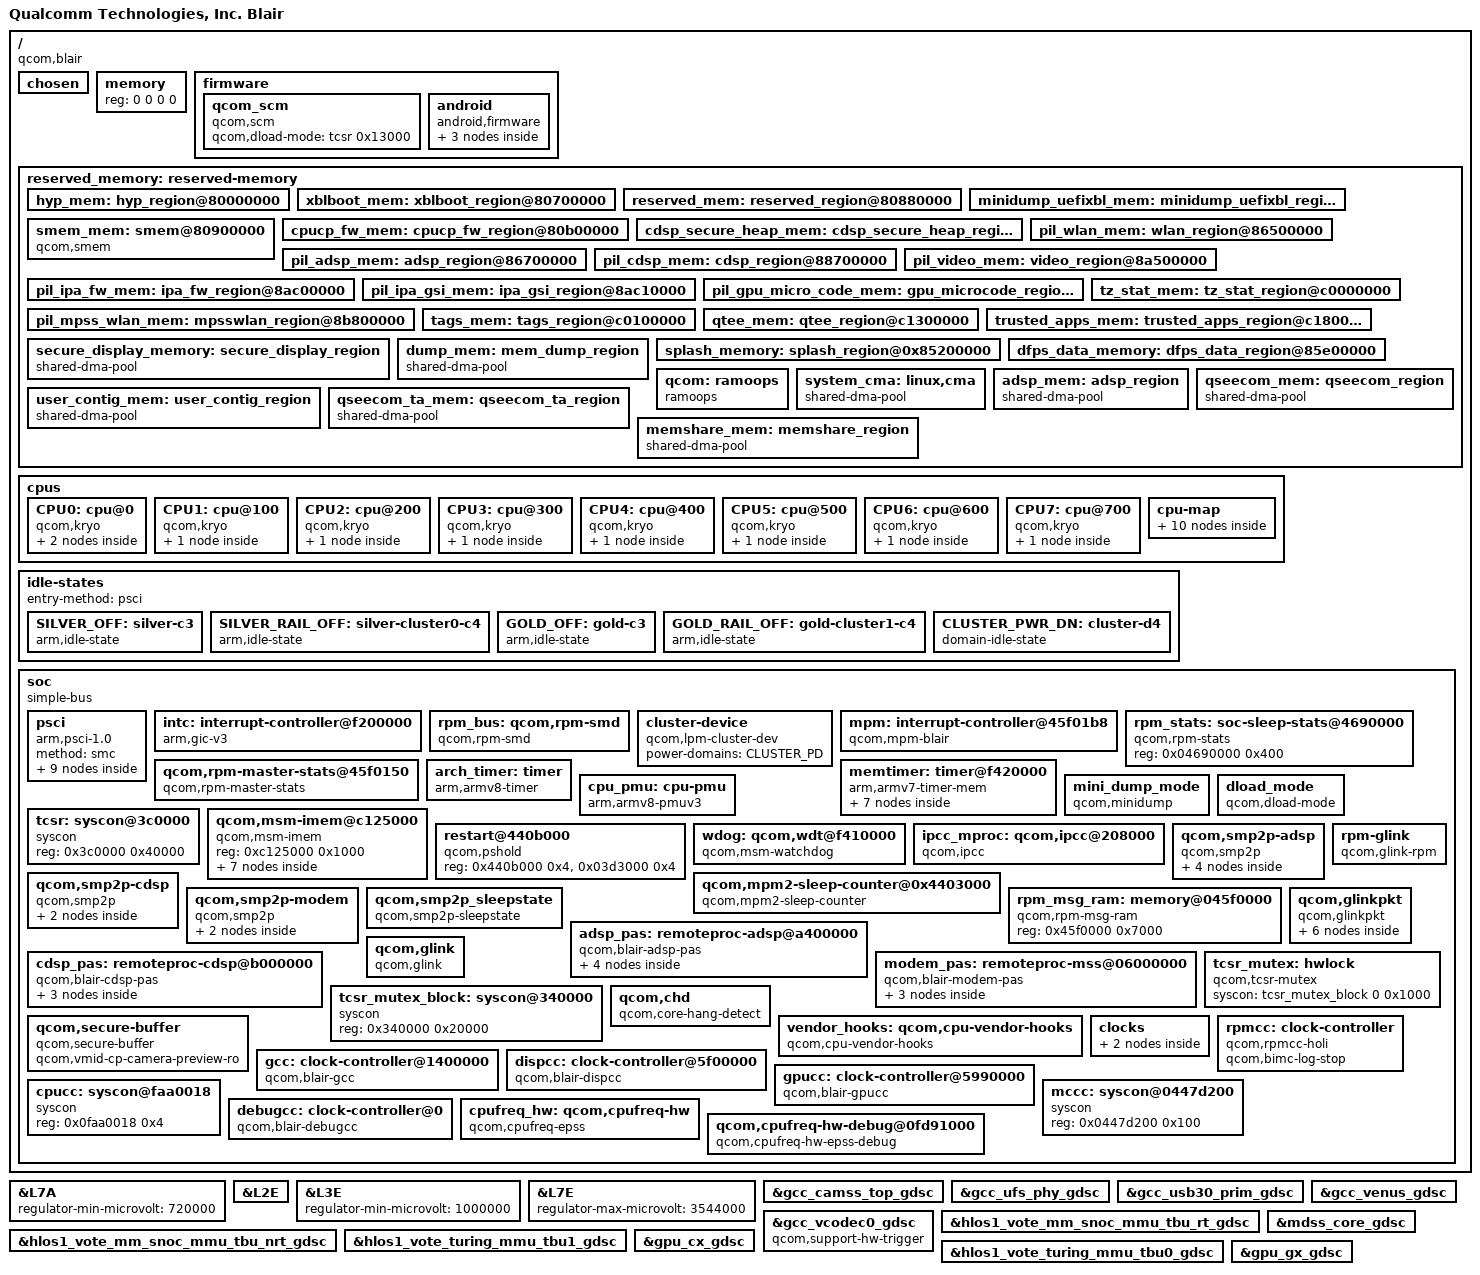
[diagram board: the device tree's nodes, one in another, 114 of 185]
#include <dt-bindings/interrupt-controller/arm-gic.h>
#include <dt-bindings/soc/qcom,ipcc.h>
#include <dt-bindings/clock/qcom,dispcc-blair.h>
#include <dt-bindings/clock/qcom,gcc-blair.h>
#include <dt-bindings/clock/qcom,gpucc-blair.h>
#include <dt-bindings/clock/qcom,rpmcc.h>

/ {
	model = "Qualcomm Technologies, Inc. Blair";
	compatible = "qcom,blair";
	qcom,msm-id = <507 0x10000>;
	interrupt-parent = <&intc>;

	#address-cells = <2>;
	#size-cells = <2>;
	chosen {
		bootargs = "log_buf_len=256K rcupdate.rcu_expedited=1 rcu_nocbs=0-7 kpti=off nmi_watchdog=0 nosoftlockup nowatchdog cpufreq.default_governor=performance";
	};

	memory { device_type = "memory"; reg = <0 0 0 0>; };

	firmware: firmware { };

	reserved_memory: reserved-memory { };

	cpus {
		#address-cells = <2>;
		#size-cells = <0>;

		CPU0: cpu@0 {
			device_type = "cpu";
			compatible = "qcom,kryo";
			reg = <0x0 0x0>;
			enable-method = "psci";
			cpu-idle-states = <&SILVER_OFF &SILVER_RAIL_OFF>;
			power-domains = <&CPU_PD0>;
			power-domain-names = "psci";
			cpu-release-addr = <0x0 0x50000000>;
			next-level-cache = <&L2_0>;
			qcom,freq-domain = <&cpufreq_hw 0>;
			L2_0: l2-cache {
			      compatible = "arm,arch-cache";
			      cache-level = <2>;
			      next-level-cache = <&L3_0>;

				L3_0: l3-cache {
				      compatible = "arm,arch-cache";
				      cache-level = <3>;
				};
			};
		};

		CPU1: cpu@100 {
			device_type = "cpu";
			compatible = "qcom,kryo";
			reg = <0x0 0x100>;
			enable-method = "psci";
			cpu-idle-states = <&SILVER_OFF &SILVER_RAIL_OFF>;
			power-domains = <&CPU_PD1>;
			power-domain-names = "psci";
			cpu-release-addr = <0x0 0x50000000>;
			next-level-cache = <&L2_1>;
			qcom,freq-domain = <&cpufreq_hw 0>;
			L2_1: l2-cache {
			      compatible = "arm,arch-cache";
			      cache-level = <2>;
			      next-level-cache = <&L3_0>;
			};
		};

		CPU2: cpu@200 {
			device_type = "cpu";
			compatible = "qcom,kryo";
			reg = <0x0 0x200>;
			enable-method = "psci";
			cpu-idle-states = <&SILVER_OFF &SILVER_RAIL_OFF>;
			power-domains = <&CPU_PD2>;
			power-domain-names = "psci";
			cpu-release-addr = <0x0 0x50000000>;
			next-level-cache = <&L2_2>;
			qcom,freq-domain = <&cpufreq_hw 0>;
			L2_2: l2-cache {
			      compatible = "arm,arch-cache";
			      cache-level = <2>;
			      next-level-cache = <&L3_0>;
			};
		};

		CPU3: cpu@300 {
			device_type = "cpu";
			compatible = "qcom,kryo";
			reg = <0x0 0x300>;
			enable-method = "psci";
			cpu-idle-states = <&SILVER_OFF &SILVER_RAIL_OFF>;
			power-domains = <&CPU_PD3>;
			power-domain-names = "psci";
			cpu-release-addr = <0x0 0x50000000>;
			next-level-cache = <&L2_3>;
			qcom,freq-domain = <&cpufreq_hw 0>;
			L2_3: l2-cache {
			      compatible = "arm,arch-cache";
			      cache-level = <2>;
			      next-level-cache = <&L3_0>;
			};
		};

		CPU4: cpu@400 {
			device_type = "cpu";
			compatible = "qcom,kryo";
			reg = <0x0 0x400>;
			enable-method = "psci";
			cpu-idle-states = <&SILVER_OFF &SILVER_RAIL_OFF>;
			power-domains = <&CPU_PD4>;
			power-domain-names = "psci";
			cpu-release-addr = <0x0 0x50000000>;
			next-level-cache = <&L2_4>;
			qcom,freq-domain = <&cpufreq_hw 0>;
			L2_4: l2-cache {
			      compatible = "arm,arch-cache";
			      cache-level = <2>;
			      next-level-cache = <&L3_0>;
			};
		};

		CPU5: cpu@500 {
			device_type = "cpu";
			compatible = "qcom,kryo";
			reg = <0x0 0x500>;
			enable-method = "psci";
			cpu-idle-states = <&SILVER_OFF &SILVER_RAIL_OFF>;
			power-domains = <&CPU_PD5>;
			power-domain-names = "psci";
			cpu-release-addr = <0x0 0x50000000>;
			next-level-cache = <&L2_5>;
			qcom,freq-domain = <&cpufreq_hw 0>;
			L2_5: l2-cache {
			      compatible = "arm,arch-cache";
			      cache-level = <2>;
			      next-level-cache = <&L3_0>;
			};
		};

		CPU6: cpu@600 {
			device_type = "cpu";
			compatible = "qcom,kryo";
			reg = <0x0 0x600>;
			enable-method = "psci";
			cpu-idle-states = <&GOLD_OFF &GOLD_RAIL_OFF>;
			power-domains = <&CPU_PD6>;
			power-domain-names = "psci";
			cpu-release-addr = <0x0 0x50000000>;
			next-level-cache = <&L2_6>;
			qcom,freq-domain = <&cpufreq_hw 1>;
			L2_6: l2-cache {
			      compatible = "arm,arch-cache";
			      cache-level = <2>;
			      next-level-cache = <&L3_0>;
			};
		};

		CPU7: cpu@700 {
			device_type = "cpu";
			compatible = "qcom,kryo";
			reg = <0x0 0x700>;
			enable-method = "psci";
			cpu-idle-states = <&GOLD_OFF &GOLD_RAIL_OFF>;
			power-domains = <&CPU_PD7>;
			power-domain-names = "psci";
			cpu-release-addr = <0x0 0x50000000>;
			next-level-cache = <&L2_7>;
			qcom,freq-domain = <&cpufreq_hw 1>;
			L2_7: l2-cache {
			      compatible = "arm,arch-cache";
			      cache-level = <2>;
			      next-level-cache = <&L3_0>;
			};
		};

		cpu-map {
			cluster0 {
				core0 {
					cpu = <&CPU0>;
				};

				core1 {
					cpu = <&CPU1>;
				};

				core2 {
					cpu = <&CPU2>;
				};

				core3 {
					cpu = <&CPU3>;
				};

				core4 {
					cpu = <&CPU4>;
				};

				core5 {
					cpu = <&CPU5>;
				};
			};

			cluster1 {
				core0 {
					cpu = <&CPU6>;
				};

				core1 {
					cpu = <&CPU7>;
				};
			};

		};
	};

	idle-states {
		entry-method = "psci";

		SILVER_OFF: silver-c3 {  /* C3 */
			compatible = "arm,idle-state";
			idle-state-name = "pc";
			entry-latency-us = <549>;
			exit-latency-us = <901>;
			min-residency-us = <1774>;
			arm,psci-suspend-param = <0x40000003>;
			local-timer-stop;
		};

		SILVER_RAIL_OFF: silver-cluster0-c4 { /* C4 */
			compatible = "arm,idle-state";
			idle-state-name = "rail-pc";
			entry-latency-us = <702>;
			exit-latency-us = <915>;
			min-residency-us = <4001>;
			arm,psci-suspend-param = <0x40000004>;
			local-timer-stop;
		};

		GOLD_OFF: gold-c3 {  /* C3 */
			compatible = "arm,idle-state";
			idle-state-name = "pc";
			entry-latency-us = <523>;
			exit-latency-us = <1244>;
			min-residency-us = <2207>;
			arm,psci-suspend-param = <0x40000003>;
			local-timer-stop;
		};

		GOLD_RAIL_OFF: gold-cluster1-c4 { /* C4 */
			compatible = "arm,idle-state";
			idle-state-name = "rail-pc";
			entry-latency-us = <526>;
			exit-latency-us = <1854>;
			min-residency-us = <5555>;
			arm,psci-suspend-param = <0x40000004>;
			local-timer-stop;
		};

		CLUSTER_PWR_DN: cluster-d4 { /* D4 */
			compatible = "domain-idle-state";
			idle-state-name = "l3-pc";
			entry-latency-us = <2752>;
			exit-latency-us = <3038>;
			min-residency-us = <6118>;
			arm,psci-suspend-param = <0x41000044>;
		};
	};

	soc: soc { };

};

#include "blair-dma-heaps.dtsi"

&reserved_memory {
	#address-cells = <2>;
	#size-cells = <2>;
	ranges;

	hyp_mem: hyp_region@80000000 {
		no-map;
		reg = <0x0 0x80000000 0x0 0x600000>;
	};

	/* only reserve part of XBL BOOT */
	xblboot_mem: xblboot_region@80700000 {
		no-map;
		reg = <0x0 0x80700000 0x0 0x100000>;
	};

	reserved_mem: reserved_region@80880000 {
		no-map;
		reg = <0x0 0x80880000 0x0 0x4000>;
	};

	minidump_uefixbl_mem: minidump_uefixbl_region@80884000 {
		no-map;
		reg = <0x0 0x80884000 0x0 0x10000>;
	};

	/* secdata can be reused by apps */

	/* smem region having compatible driver */
	smem_mem: smem@80900000 {
		compatible = "qcom,smem";
		reg = <0x0 0x80900000 0x0 0x200000>;
		hwlocks = <&tcsr_mutex 3>;
		no-map;
	};

	cpucp_fw_mem: cpucp_fw_region@80b00000 {
		no-map;
		reg = <0x0 0x80b00000 0x0 0x100000>;
	};

	cdsp_secure_heap_mem: cdsp_secure_heap_region@80c00000 {
		no-map;
		reg = <0x0 0x80c00000 0x0 0x1e00000>;
	};

	pil_wlan_mem: wlan_region@86500000 {
		no-map;
		reg = <0x0 0x86500000 0x0 0x200000>;
	};

	pil_adsp_mem: adsp_region@86700000 {
		no-map;
		reg = <0x0 0x86700000 0x0 0x2000000>;
	};

	pil_cdsp_mem: cdsp_region@88700000 {
		no-map;
		reg = <0x0 0x88700000 0x0 0x1e00000>;
	};

	pil_video_mem: video_region@8a500000 {
		no-map;
		reg = <0x0 0x8a500000 0x0 0x700000>;
	};

	pil_ipa_fw_mem: ipa_fw_region@8ac00000 {
		no-map;
		reg = <0x0 0x8ac00000 0x0 0x10000>;
	};

	pil_ipa_gsi_mem: ipa_gsi_region@8ac10000 {
		no-map;
		reg = <0x0 0x8ac10000 0x0 0xa000>;
	};

	pil_gpu_micro_code_mem: gpu_microcode_region@8ac1a000 {
		no-map;
		reg = <0x0 0x8ac1a000 0x0 0x2000>;
	};

	pil_mpss_wlan_mem: mpsswlan_region@8b800000 {
		no-map;
		reg = <0x0 0x8b800000 0x0 0x10000000>;
	};

	tz_stat_mem: tz_stat_region@c0000000 {
		no-map;
		reg = <0x0 0xc0000000 0x0 0x100000>;
	};

	tags_mem: tags_region@c0100000 {
		no-map;
		reg = <0x0 0xc0100000 0x0 0x1200000>;
	};

	qtee_mem: qtee_region@c1300000 {
		no-map;
		reg = <0x0 0xc1300000 0x0 0x500000>;
	};

	trusted_apps_mem: trusted_apps_region@c1800000 {
		no-map;
		reg = <0x0 0xc1800000 0x0 0x3900000>;
	};

	secure_display_memory: secure_display_region {
		compatible = "shared-dma-pool";
		alloc-ranges = <0 0x00000000 0 0xffffffff>;
		reusable;
		alignment = <0 0x400000>;
		size = <0 0x5c00000>;
	};

	dump_mem: mem_dump_region {
		compatible = "shared-dma-pool";
		alloc-ranges = <0x0 0x00000000 0x0 0xffffffff>;
		reusable;
		size = <0 0x800000>;
	};

	splash_memory: splash_region@0x85200000 {
		reg = <0x0 0x85200000 0x0 0x00c00000>;
		label = "cont_splash_region";
	};

	dfps_data_memory: dfps_data_region@85e00000 {
		reg = <0x0 0x85e00000 0x0 0x00100000>;
		label = "dfps_data_region";
	};

	qcom: ramoops {
		compatible = "ramoops";
		reg = <0x0 0xd0000000 0x0 0x200000>;
		pmsg-size = <0x200000>;
		mem-type = <2>;
	};

	/* global autoconfigured region for contiguous allocations */
	system_cma: linux,cma {
		compatible = "shared-dma-pool";
		alloc-ranges = <0x0 0x00000000 0x0 0xffffffff>;
		reusable;
		alignment = <0x0 0x400000>;
		size = <0x0 0x2000000>;
		linux,cma-default;
	};

	adsp_mem: adsp_region {
		compatible = "shared-dma-pool";
		alloc-ranges = <0 0x00000000 0 0xffffffff>;
		reusable;
		alignment = <0 0x400000>;
		size = <0 0x800000>;
	};

	user_contig_mem: user_contig_region {
		compatible = "shared-dma-pool";
		alloc-ranges = <0x0 0x00000000 0x0 0xffffffff>;
		reusable;
		alignment = <0x0 0x400000>;
		size = <0x0 0x1000000>;
	};

	qseecom_mem: qseecom_region {
		compatible = "shared-dma-pool";
		alloc-ranges = <0x0 0x00000000 0x0 0xffffffff>;
		reusable;
		alignment = <0x0 0x400000>;
		size = <0x0 0x1400000>;
	};

	qseecom_ta_mem: qseecom_ta_region {
		compatible = "shared-dma-pool";
		alloc-ranges = <0x0 0x00000000 0x0 0xffffffff>;
		reusable;
		alignment = <0x0 0x400000>;
		size = <0x0 0x1000000>;
	};

	memshare_mem: memshare_region {
		compatible = "shared-dma-pool";
		no-map;
		alloc-ranges = <0x0 0x00000000 0x0 0xffffffff>;
		alignment = <0x0 0x100000>;
		size = <0x0 0x800000>;
	};
};

&soc {
	#address-cells = <1>;
	#size-cells = <1>;
	ranges = <0 0 0 0xffffffff>;
	compatible = "simple-bus";

	psci {
		compatible = "arm,psci-1.0";
		method = "smc";

		CPU_PD0: cpu-pd0 {
			#power-domain-cells = <0>;
			power-domains = <&CLUSTER_PD>;
		};

		CPU_PD1: cpu-pd1 {
			#power-domain-cells = <0>;
			power-domains = <&CLUSTER_PD>;
		};

		CPU_PD2: cpu-pd2 {
			#power-domain-cells = <0>;
			power-domains = <&CLUSTER_PD>;
		};

		CPU_PD3: cpu-pd3 {
			#power-domain-cells = <0>;
			power-domains = <&CLUSTER_PD>;
		};

		CPU_PD4: cpu-pd4 {
			#power-domain-cells = <0>;
			power-domains = <&CLUSTER_PD>;
		};

		CPU_PD5: cpu-pd5 {
			#power-domain-cells = <0>;
			power-domains = <&CLUSTER_PD>;
		};

		CPU_PD6: cpu-pd6 {
			#power-domain-cells = <0>;
			power-domains = <&CLUSTER_PD>;
		};

		CPU_PD7: cpu-pd7 {
			#power-domain-cells = <0>;
			power-domains = <&CLUSTER_PD>;
		};

		CLUSTER_PD: cluster-pd {
			#power-domain-cells = <0>;
			domain-idle-states = <&CLUSTER_PWR_DN>;
		};
	};

	intc: interrupt-controller@f200000 {
		compatible = "arm,gic-v3";
		#interrupt-cells = <3>;
		interrupt-controller;
		#redistributor-regions = <1>;
		redistributor-stride = <0x0 0x20000>;
		reg = <0xf200000 0x10000>,     /* GICD */
		      <0xf240000 0x100000>;    /* GICR * 8 */
		interrupts = <GIC_PPI 8 IRQ_TYPE_LEVEL_HIGH>;
	};

	rpm_bus: qcom,rpm-smd {
		compatible = "qcom,rpm-smd";
		rpm-channel-name = "rpm_requests";
		interrupt-parent = <&ipcc_mproc>;
		interrupts = <IPCC_CLIENT_AOP
			      IPCC_MPROC_SIGNAL_GLINK_QMP
			      IRQ_TYPE_EDGE_RISING>;
		rpm-channel-type = <15>; /* SMD_APPS_RPM */
		power-domains = <&CLUSTER_PD>;
	};

	cluster-device {
		compatible = "qcom,lpm-cluster-dev";
		power-domains = <&CLUSTER_PD>;
	};

	mpm: interrupt-controller@45f01b8 {
		compatible = "qcom,mpm-blair", "qcom,mpm";
		reg = <0x45f01b8 0x1000>,
		      <0x0f40000c 0x4>,  /* MSM_APCS_GCC_BASE 4K */
		      <0xf421000 0x1000>;
		reg-names = "vmpm", "ipc", "timer";
		interrupts = <GIC_SPI 197 IRQ_TYPE_EDGE_RISING>;
		qcom,num-mpm-irqs = <96>;
		interrupt-controller;
		interrupt-parent = <&intc>;
		#interrupt-cells = <2>;
	};

	rpm_stats: soc-sleep-stats@4690000 {
		compatible = "qcom,rpm-stats";
		reg = <0x04690000 0x400>;
	};

	qcom,rpm-master-stats@45f0150 {
		compatible = "qcom,rpm-master-stats";
		reg = <0x45f0150 0x5000>;
		qcom,masters = "APSS", "MPSS", "ADSP", "CDSP", "TZ";
		qcom,master-stats-version = <2>;
		qcom,master-offset = <4096>;
	};

	arch_timer: timer {
		compatible = "arm,armv8-timer";
		interrupts = <GIC_PPI 1 (GIC_CPU_MASK_SIMPLE(8) | IRQ_TYPE_LEVEL_LOW)>,
			     <GIC_PPI 2 (GIC_CPU_MASK_SIMPLE(8) | IRQ_TYPE_LEVEL_LOW)>,
			     <GIC_PPI 3 (GIC_CPU_MASK_SIMPLE(8) | IRQ_TYPE_LEVEL_LOW)>,
			     <GIC_PPI 0 (GIC_CPU_MASK_SIMPLE(8) | IRQ_TYPE_LEVEL_LOW)>;
		clock-frequency = <19200000>;
	};

	memtimer: timer@f420000 {
		#address-cells = <1>;
		#size-cells = <1>;
		ranges;
		compatible = "arm,armv7-timer-mem";
		reg = <0x0f420000 0x1000>;
		clock-frequency = <19200000>;

		frame@f421000 {
			frame-number = <0>;
			interrupts = <GIC_SPI 8 IRQ_TYPE_LEVEL_HIGH>,
				     <GIC_SPI 6 IRQ_TYPE_LEVEL_HIGH>;
			reg = <0x0f421000 0x1000>,
			      <0x0f422000 0x1000>;
		};

		frame@f423000 {
			frame-number = <1>;
			interrupts = <GIC_SPI 9 IRQ_TYPE_LEVEL_HIGH>;
			reg = <0xf243000 0x1000>;
			status = "disabled";
		};

		frame@f425000 {
			frame-number = <2>;
			interrupts = <GIC_SPI 10 IRQ_TYPE_LEVEL_HIGH>;
			reg = <0xf425000 0x1000>;
			status = "disabled";
		};

		frame@f427000 {
			frame-number = <3>;
			interrupts = <GIC_SPI 11 IRQ_TYPE_LEVEL_HIGH>;
			reg = <0xf427000 0x1000>;
			status = "disabled";
		};

		frame@f429000 {
			frame-number = <4>;
			interrupts = <GIC_SPI 12 IRQ_TYPE_LEVEL_HIGH>;
			reg = <0xf429000 0x1000>;
			status = "disabled";
		};

		frame@f42b000 {
			frame-number = <5>;
			interrupts = <GIC_SPI 13 IRQ_TYPE_LEVEL_HIGH>;
			reg = <0xf42b000 0x1000>;
			status = "disabled";
		};

		frame@f42d000 {
			frame-number = <6>;
			interrupts = <GIC_SPI 14 IRQ_TYPE_LEVEL_HIGH>;
			reg = <0xf42d000 0x1000>;
			status = "disabled";
		};
	};

	cpu_pmu: cpu-pmu {
		compatible = "arm,armv8-pmuv3";
		qcom,irq-is-percpu;
		interrupts = <GIC_PPI 5 IRQ_TYPE_LEVEL_HIGH>;
	};

	mini_dump_mode {
		compatible = "qcom,minidump";
		status = "ok";
	};

	dload_mode {
		compatible = "qcom,dload-mode";
	};

	tcsr: syscon@3c0000 {
		compatible = "syscon";
		reg = <0x3c0000 0x40000>;
	};

	qcom,msm-imem@c125000 {
		compatible = "qcom,msm-imem";
		reg = <0xc125000 0x1000>;
		ranges = <0x0 0xc125000 0x1000>;
		#address-cells = <1>;
		#size-cells = <1>;

		mem_dump_table@10 {
			compatible = "qcom,msm-imem-mem_dump_table";
			reg = <0x10 0x8>;
		};

		restart_reason@65c {
			compatible = "qcom,msm-imem-restart_reason";
			reg = <0x65c 0x4>;
		};

		dload_type@1c {
			compatible = "qcom,msm-imem-dload-type";
			reg = <0x1c 0x4>;
		};

		boot_stats@6b0 {
			compatible = "qcom,msm-imem-boot_stats";
			reg = <0x6b0 0x20>;
		};

		kaslr_offset@6d0 {
			compatible = "qcom,msm-imem-kaslr_offset";
			reg = <0x6d0 0xc>;
		};

		pil@94c {
			compatible = "qcom,msm-imem-pil";
			reg = <0x94c 0xc8>;
		};

		diag_dload@c8 {
			compatible = "qcom,msm-imem-diag-dload";
			reg = <0xc8 0xc8>;
		};
	};

	restart@440b000 {
		compatible = "qcom,pshold";
		reg = <0x440b000 0x4>, <0x03d3000 0x4>;
		reg-names = "pshold-base", "tcsr-boot-misc-detect";
	};

	wdog: qcom,wdt@f410000 {
		compatible = "qcom,msm-watchdog";
		reg = <0xf410000 0x1000>;
		reg-names = "wdt-base";
		interrupts = <0 0 IRQ_TYPE_LEVEL_HIGH>,
					<0 1 IRQ_TYPE_LEVEL_HIGH>;
		qcom,bark-time = <11000>;
		qcom,pet-time = <9360>;
		qcom,ipi-ping;
		qcom,wakeup-enable;
	};

	ipcc_mproc: qcom,ipcc@208000 {
		compatible = "qcom,ipcc";
		reg = <0x208000 0x1000>;
		interrupts = <GIC_SPI 334 IRQ_TYPE_LEVEL_HIGH>;
		interrupt-controller;
		#interrupt-cells = <3>;
		#mbox-cells = <2>;
	};

	qcom,mpm2-sleep-counter@0x4403000 {
		compatible = "qcom,mpm2-sleep-counter";
		reg = <0x4403000 0x1000>;
		clock-frequency = <32768>;
	};

	qcom,smp2p-adsp {
		compatible = "qcom,smp2p";
		qcom,smem = <443>, <429>;
		interrupt-parent = <&ipcc_mproc>;
		interrupts = <IPCC_CLIENT_LPASS IPCC_MPROC_SIGNAL_SMP2P
			      IRQ_TYPE_EDGE_RISING>;
		mboxes = <&ipcc_mproc IPCC_CLIENT_LPASS
			  IPCC_MPROC_SIGNAL_SMP2P>;
		qcom,local-pid = <0>;
		qcom,remote-pid = <2>;

		adsp_smp2p_out: master-kernel {
			qcom,entry-name = "master-kernel";
			#qcom,smem-state-cells = <1>;
		};

		adsp_smp2p_in: slave-kernel {
			qcom,entry-name = "slave-kernel";
			interrupt-controller;
			#interrupt-cells = <2>;
		};

		sleepstate_smp2p_out: sleepstate-out {
			qcom,entry-name = "sleepstate";
			#qcom,smem-state-cells = <1>;
		};

		sleepstate_smp2p_in: qcom,sleepstate-in {
			qcom,entry-name = "sleepstate_see";
			interrupt-controller;
			#interrupt-cells = <2>;
		};
	};

	qcom,smp2p-cdsp {
		compatible = "qcom,smp2p";
		qcom,smem = <94>, <432>;
		interrupt-parent = <&ipcc_mproc>;
		interrupts = <IPCC_CLIENT_CDSP IPCC_MPROC_SIGNAL_SMP2P
			      IRQ_TYPE_EDGE_RISING>;
		mboxes = <&ipcc_mproc IPCC_CLIENT_CDSP
			  IPCC_MPROC_SIGNAL_SMP2P>;
		qcom,local-pid = <0>;
		qcom,remote-pid = <5>;

		cdsp_smp2p_out: master-kernel {
			qcom,entry-name = "master-kernel";
			#qcom,smem-state-cells = <1>;
		};

		cdsp_smp2p_in: slave-kernel {
			qcom,entry-name = "slave-kernel";
			interrupt-controller;
			#interrupt-cells = <2>;
		};
	};

	qcom,smp2p-modem {
		compatible = "qcom,smp2p";
		qcom,smem = <435>, <428>;
		interrupt-parent = <&ipcc_mproc>;
		interrupts = <IPCC_CLIENT_MPSS IPCC_MPROC_SIGNAL_SMP2P
			      IRQ_TYPE_EDGE_RISING>;
		mboxes = <&ipcc_mproc IPCC_CLIENT_MPSS
			  IPCC_MPROC_SIGNAL_SMP2P>;
		qcom,local-pid = <0>;
		qcom,remote-pid = <1>;

		modem_smp2p_out: master-kernel {
			qcom,entry-name = "master-kernel";
			#qcom,smem-state-cells = <1>;
		};

		modem_smp2p_in: slave-kernel {
			qcom,entry-name = "slave-kernel";
			interrupt-controller;
			#interrupt-cells = <2>;
		};
	};

	qcom,smp2p_sleepstate {
		compatible = "qcom,smp2p-sleepstate";
		qcom,smem-states = <&sleepstate_smp2p_out 0>;
		interrupt-parent = <&sleepstate_smp2p_in>;
		interrupts = <0 0>;
		interrupt-names = "smp2p-sleepstate-in";
	};

	rpm_msg_ram: memory@045f0000 {
		compatible = "qcom,rpm-msg-ram";
		reg = <0x45f0000 0x7000>;
	};

	rpm-glink {
		compatible = "qcom,glink-rpm";
		qcom,rpm-msg-ram = <&rpm_msg_ram>;
		mboxes = <&ipcc_mproc IPCC_CLIENT_AOP
			  IPCC_MPROC_SIGNAL_GLINK_QMP>;
		mbox-names = "rpm_smem";
		interrupt-parent = <&ipcc_mproc>;
		interrupts = <IPCC_CLIENT_AOP
			      IPCC_MPROC_SIGNAL_GLINK_QMP
			      IRQ_TYPE_EDGE_RISING>;
	};

	adsp_pas: remoteproc-adsp@a400000 {
		compatible = "qcom,blair-adsp-pas";
		reg = <0xa400000 0x00100>;
		status = "ok";

		memory-region = <&pil_adsp_mem>;

		interrupts-extended = <&intc GIC_SPI 282 IRQ_TYPE_LEVEL_HIGH>,
			<&adsp_smp2p_in 0 0>,
			<&adsp_smp2p_in 2 0>,
			<&adsp_smp2p_in 1 0>,
			<&adsp_smp2p_in 3 0>;

		interrupt-names = "qcom,wdog",
			"err-fatal",
			"proxy-unvote",
			"err-ready",
			"stop-ack";

		qcom,smem-states = <&adsp_smp2p_out 0>;
		qcom,smem-state-names = "stop";

		glink_edge: glink-edge {
			qcom,remote-pid = <2>;
			transport = "smem";
			mboxes = <&ipcc_mproc IPCC_CLIENT_LPASS
				  IPCC_MPROC_SIGNAL_GLINK_QMP>;
			mbox-names = "adsp_smem";
			interrupt-parent = <&ipcc_mproc>;
			interrupts = <IPCC_CLIENT_LPASS
				      IPCC_MPROC_SIGNAL_GLINK_QMP
				      IRQ_TYPE_EDGE_RISING>;

			label = "adsp";
			qcom,glink-label = "lpass";

			qcom,adsp_qrtr {
				qcom,glink-channels = "IPCRTR";
				qcom,intents = <0x800  5
						0x2000 3
						0x4400 2>;

				qcom,no-wake-svc = <0x190>;
			};

			qcom,pmic_glink_rpmsg {
				qcom,glink-channels = "PMIC_RTR_ADSP_APPS";
			};

			qcom,pmic_glink_log_rpmsg {
				qcom,glink-channels = "PMIC_LOGS_ADSP_APPS";
				qcom,intents = <0x800 5
						0xc00 3 >;
			};
		};
	};

	cdsp_pas: remoteproc-cdsp@b000000 {
		compatible = "qcom,blair-cdsp-pas";
		reg = <0xb000000 0x100000>;
		status = "ok";

		memory-region = <&pil_cdsp_mem>;

		interrupts-extended = <&intc GIC_SPI 265 IRQ_TYPE_LEVEL_HIGH>,
			<&cdsp_smp2p_in 0 0>,
			<&cdsp_smp2p_in 2 0>,
			<&cdsp_smp2p_in 1 0>,
			<&cdsp_smp2p_in 3 0>;

		interrupt-names = "qcom,wdog",
			"err-fatal",
			"proxy-unvote",
			"err-ready",
			"stop-ack";

		qcom,smem-states = <&cdsp_smp2p_out 0>;
		qcom,smem-state-names = "stop";

		glink-edge {
			qcom,remote-pid = <5>;
			transport = "smem";
			mboxes = <&ipcc_mproc IPCC_CLIENT_CDSP
				  IPCC_MPROC_SIGNAL_GLINK_QMP>;
			mbox-names = "cdsp_smem";
			interrupt-parent = <&ipcc_mproc>;
			interrupts = <IPCC_CLIENT_CDSP
				      IPCC_MPROC_SIGNAL_GLINK_QMP
				      IRQ_TYPE_EDGE_RISING>;

			label = "cdsp";
			qcom,glink-label = "cdsp";

			qcom,cdsp_qrtr {
				qcom,glink-channels = "IPCRTR";
				qcom,intents = <0x800  5
						0x2000 3
						0x4400 2>;
			};

			qcom,msm_cdsprm_rpmsg {
				compatible = "qcom,msm-cdsprm-rpmsg";
				qcom,glink-channels = "cdsprmglink-apps-dsp";
				qcom,intents = <0x20 12>;
			};
		};
	};

	modem_pas: remoteproc-mss@06000000 {
		compatible = "qcom,blair-modem-pas";
		reg = <0x06000000 0x100>;
		status = "ok";

		memory-region = <&pil_mpss_wlan_mem>;

		interrupts-extended = <&intc GIC_SPI 307 IRQ_TYPE_EDGE_RISING>,
			<&modem_smp2p_in 0 0>,
			<&modem_smp2p_in 2 0>,
			<&modem_smp2p_in 1 0>,
			<&modem_smp2p_in 3 0>,
			<&modem_smp2p_in 7 0>;

		interrupt-names = "qcom,wdog",
			"err-fatal",
			"proxy-unvote",
			"err-ready",
			"stop-ack",
			"shutdown-ack";

		qcom,smem-states = <&modem_smp2p_out 0>;
		qcom,smem-state-names = "stop";

		glink-edge {
			qcom,remote-pid = <1>;
			transport = "smem";
			mboxes = <&ipcc_mproc IPCC_CLIENT_MPSS
				  IPCC_MPROC_SIGNAL_GLINK_QMP>;
			mbox-names = "mpss_smem";
			interrupt-parent = <&ipcc_mproc>;
			interrupts = <IPCC_CLIENT_MPSS
				      IPCC_MPROC_SIGNAL_GLINK_QMP
				      IRQ_TYPE_EDGE_RISING>;

			label = "modem";
			qcom,glink-label = "mpss";

			qcom,modem_qrtr {
				qcom,glink-channels = "IPCRTR";
				qcom,low-latency;
				qcom,intents = <0x800  5
						0x2000 3
						0x4400 2>;
			};

			qcom,modem_ds {
				qcom,glink-channels = "DS";
				qcom,intents = <0x4000 0x2>;
			};
		};
	};

	qcom,glinkpkt {
		compatible = "qcom,glinkpkt";

		qcom,glinkpkt-at-mdm0 {
			qcom,glinkpkt-edge = "mpss";
			qcom,glinkpkt-ch-name = "DS";
			qcom,glinkpkt-dev-name = "at_mdm0";
		};

		qcom,glinkpkt-apr-apps2 {
			qcom,glinkpkt-edge = "adsp";
			qcom,glinkpkt-ch-name = "apr_apps2";
			qcom,glinkpkt-dev-name = "apr_apps2";
		};

		qcom,glinkpkt-data40-cntl {
			qcom,glinkpkt-edge = "mpss";
			qcom,glinkpkt-ch-name = "DATA40_CNTL";
			qcom,glinkpkt-dev-name = "smdcntl8";
		};

		qcom,glinkpkt-data1 {
			qcom,glinkpkt-edge = "mpss";
			qcom,glinkpkt-ch-name = "DATA1";
			qcom,glinkpkt-dev-name = "smd7";
		};

		qcom,glinkpkt-data4 {
			qcom,glinkpkt-edge = "mpss";
			qcom,glinkpkt-ch-name = "DATA4";
			qcom,glinkpkt-dev-name = "smd8";
		};

		qcom,glinkpkt-data11 {
			qcom,glinkpkt-edge = "mpss";
			qcom,glinkpkt-ch-name = "DATA11";
			qcom,glinkpkt-dev-name = "smd11";
		};
	};

	qcom,glink {
		compatible = "qcom,glink";
	};

	tcsr_mutex_block: syscon@340000 {
		compatible = "syscon";
		reg = <0x340000 0x20000>;
	};

	tcsr_mutex: hwlock {
		compatible = "qcom,tcsr-mutex";
		syscon = <&tcsr_mutex_block 0 0x1000>;
		#hwlock-cells = <1>;
	};

	qcom,chd {
		compatible = "qcom,core-hang-detect";
		label = "core";
		qcom,threshold-arr = <0x0F800058 0x0F810058 0x0F820058 0x0F830058
			0x0F840058 0x0F850058 0x0F860058 0x0F870058>;
		qcom,config-arr = <0x0F800060 0x0F810060 0x0F820060 0x0F830060
			0x0F840060 0x0F850060 0x0F860060 0x0F870060>;
	};

	vendor_hooks: qcom,cpu-vendor-hooks {
		compatible = "qcom,cpu-vendor-hooks";
	};

	qcom,secure-buffer {
		compatible = "qcom,secure-buffer";
		qcom,vmid-cp-camera-preview-ro;
	};

	clocks {
		xo_board: xo-board {
			compatible = "fixed-clock";
			clock-frequency = <38400000>;
			clock-output-names = "xo_board";
			#clock-cells = <0>;
		};

		sleep_clk: sleep-clk {
			compatible = "fixed-clock";
			clock-frequency = <32764>;
			clock-output-names = "chip_sleep_clk";
			#clock-cells = <0>;
		};
	};

	rpmcc: clock-controller {
		compatible = "qcom,rpmcc-holi";
		qcom,bimc-log-stop;
		#clock-cells = <1>;
		#reset-cells = <1>;
	};

	gcc: clock-controller@1400000 {
		compatible = "qcom,blair-gcc", "syscon";
		reg = <0x1400000 0x1f0000>;
		reg_names = "cc_base";
		vdd_cx-supply = <&S2E_LEVEL>;
		vdd_mx-supply = <&S1E_LEVEL>;
		clocks = <&rpmcc RPM_SMD_XO_CLK_SRC>,
			 <&rpmcc RPM_SMD_XO_A_CLK_SRC>,
			 <&sleep_clk>;
		clock-names = "bi_tcxo", "bi_tcxo_ao", "sleep_clk";
		#clock-cells = <1>;
		#reset-cells = <1>;
	};

	dispcc: clock-controller@5f00000 {
		compatible = "qcom,blair-dispcc", "syscon";
		reg = <0x5f00000 0x20000>;
		reg-names = "cc_base";
		vdd_cx-supply = <&S2E_LEVEL>;
		clocks = <&rpmcc RPM_SMD_XO_CLK_SRC>,
			 <&gcc GCC_DISP_GPLL0_DIV_CLK_SRC>;
		clock-names = "bi_tcxo", "gcc_disp_gpll0_clk";
		#clock-cells = <1>;
		#reset-cells = <1>;
	};

	gpucc: clock-controller@5990000 {
		compatible = "qcom,blair-gpucc", "syscon";
		reg = <0x5990000 0x9000>;
		reg-names = "cc_base";
		vdd_cx-supply = <&S2E_LEVEL>;
		vdd_mx-supply = <&S1E_LEVEL>;
		vdd_gx-supply = <&S8A_LEVEL>;
		clocks = <&rpmcc RPM_SMD_XO_CLK_SRC>, <&gcc GCC_GPU_GPLL0_CLK_SRC>,
			<&gcc GCC_GPU_GPLL0_DIV_CLK_SRC>,
			<&gcc GCC_GPU_SNOC_DVM_GFX_CLK>;
		clock-names = "bi_tcxo", "gcc_gpu_gpll0_clk_src",
				"gcc_gpu_gpll0_div_clk_src",
				"gcc_gpu_snoc_dvm_gfx_clk";
		#clock-cells = <1>;
		#reset-cells = <1>;
	};

	cpucc: syscon@faa0018 {
		compatible = "syscon";
		reg = <0x0faa0018 0x4>;
	};

	mccc: syscon@0447d200 {
		compatible = "syscon";
		reg = <0x0447d200 0x100>;
	};

	debugcc: clock-controller@0 {
		compatible = "qcom,blair-debugcc";
		qcom,gcc = <&gcc>;
		qcom,dispcc = <&dispcc>;
		qcom,gpucc = <&gpucc>;
		qcom,cpucc = <&cpucc>;
		qcom,mccc = <&mccc>;
		clocks = <&rpmcc RPM_SMD_XO_CLK_SRC>,
			<&gcc 0>, <&gpucc 0>, <&dispcc 0>;
		clock-names = "xo_clk_src", "gcc",
			"gpucc", "dispcc";
		#clock-cells = <1>;
	};

	cpufreq_hw: qcom,cpufreq-hw {
		compatible = "qcom,cpufreq-epss";
		reg = <0x0fd91000 0x1000>, <0x0fd92000 0x1000>;
		reg-names = "freq-domain0", "freq-domain1";
		clocks = <&rpmcc RPM_SMD_XO_CLK_SRC>, <&gcc GPLL0>;
		clock-names = "xo", "alternate";
		interrupts = <GIC_SPI 30 IRQ_TYPE_LEVEL_HIGH>,
				<GIC_SPI 31 IRQ_TYPE_LEVEL_HIGH>;
		interrupt-names = "dcvsh0_int", "dcvsh1_int";
		#freq-domain-cells = <1>;
	};

	qcom,cpufreq-hw-debug@0fd91000 {
		compatible = "qcom,cpufreq-hw-epss-debug";
		qcom,freq-hw-domain = <&cpufreq_hw 0>, <&cpufreq_hw 1>;
	};
};

&firmware {
	qcom_scm {
		compatible = "qcom,scm";
		qcom,dload-mode = <&tcsr 0x13000>;
	};

	android {
		compatible = "android,firmware";
		vbmeta {
			compatible = "android,vbmeta";
			parts = "vbmeta,boot,system,vendor,dtbo";
		};

		fstab {
			compatible = "android,fstab";
			vendor {
				compatible = "android,vendor";
				dev = "/dev/block/platform/soc/4744000.sdhci/by-name/vendor";
				type = "ext4";
				mnt_flags = "ro,barrier=1,discard";
				fsmgr_flags = "wait,slotselect,avb";
				status = "ok";
			};
		};
	};
};

#include "blair-pinctrl.dtsi"
#include "pm6125-rpm-regulator.dtsi"
#include "pmr735a-rpm-regulator.dtsi"
#include "blair-regulators-pm6125.dtsi"
#include "holi-gdsc.dtsi"

&L7A {
	regulator-min-microvolt = <720000>;
};

&L2E {
	regulator-min-microvolt = <352000>;
	regulator-max-microvolt = <796000>;
};

&L3E {
	regulator-min-microvolt = <1000000>;
};

&L7E {
	regulator-max-microvolt = <3544000>;
};

&gcc_camss_top_gdsc {
	status = "ok";
};

&gcc_ufs_phy_gdsc {
	status = "ok";
};

&gcc_usb30_prim_gdsc {
	status = "ok";
};

&gcc_vcodec0_gdsc {
	qcom,support-hw-trigger;
	status = "ok";
};

&gcc_venus_gdsc {
	status = "ok";
};

&hlos1_vote_mm_snoc_mmu_tbu_rt_gdsc {
	status = "ok";
};

&hlos1_vote_mm_snoc_mmu_tbu_nrt_gdsc {
	status = "ok";
};

&hlos1_vote_turing_mmu_tbu1_gdsc {
	status = "ok";
};

&hlos1_vote_turing_mmu_tbu0_gdsc {
	status = "ok";
};

&mdss_core_gdsc {
	clocks = <&gcc GCC_DISP_AHB_CLK>;
	clock-names = "ahb_clk";
	qcom,support-hw-trigger;
	status = "ok";
};

&gpu_cx_gdsc {
	clocks = <&gcc GCC_GPU_CFG_AHB_CLK>;
	clock-names = "ahb_clk";
	parent-supply = <&S2E_LEVEL>;
	status = "ok";
};

&gpu_gx_gdsc {
	clocks = <&gcc GCC_GPU_CFG_AHB_CLK>;
	clock-names = "ahb_clk";
	parent-supply = <&S8A_LEVEL>;
	status = "ok";
};
